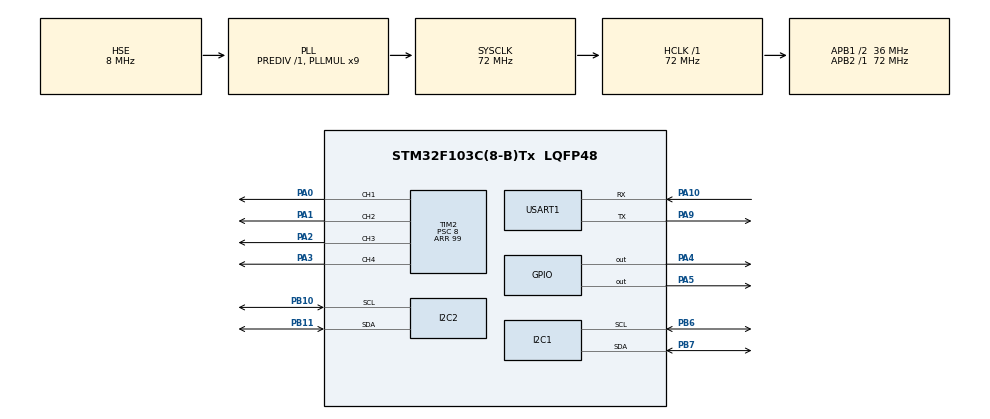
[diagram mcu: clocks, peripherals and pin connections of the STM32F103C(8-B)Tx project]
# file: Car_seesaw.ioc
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I2C2.I2C_Mode=I2C_Fast
Mcu.Family=STM32F1
Mcu.Name=STM32F103C(8-B)Tx
Mcu.Package=LQFP48
NVIC.PriorityGroup=NVIC_PRIORITYGROUP_4
NVIC.TIM1_UP_IRQn=true\:1\:0\:true\:false\:true\:true\:true
PA0-WKUP.Signal=S_TIM2_CH1_ETR
PA1.Signal=S_TIM2_CH2
PA10.Mode=Asynchronous
PA10.Signal=USART1_RX
PA13.Mode=Serial_Wire
PA13.Signal=SYS_JTMS-SWDIO
PA14.Mode=Serial_Wire
PA14.Signal=SYS_JTCK-SWCLK
PA2.Signal=S_TIM2_CH3
PA3.Signal=S_TIM2_CH4
PA4.GPIO_Speed=GPIO_SPEED_FREQ_HIGH
PA4.Signal=GPIO_Output
PA5.GPIO_Speed=GPIO_SPEED_FREQ_HIGH
PA5.Signal=GPIO_Output
PA9.Mode=Asynchronous
PA9.Signal=USART1_TX
PB10.Mode=I2C
PB10.Signal=I2C2_SCL
PB11.Mode=I2C
PB11.Signal=I2C2_SDA
PB6.Mode=I2C
PB6.Signal=I2C1_SCL
PB7.Mode=I2C
PB7.Signal=I2C1_SDA
PC14-OSC32_IN.Mode=LSE-External-Oscillator
PC14-OSC32_IN.Signal=RCC_OSC32_IN
PC15-OSC32_OUT.Mode=LSE-External-Oscillator
PC15-OSC32_OUT.Signal=RCC_OSC32_OUT
PD0-OSC_IN.Mode=HSE-External-Oscillator
PD0-OSC_IN.Signal=RCC_OSC_IN
PD1-OSC_OUT.Mode=HSE-External-Oscillator
PD1-OSC_OUT.Signal=RCC_OSC_OUT
ProjectManager.HeapSize=0x200
ProjectManager.StackSize=0x400
ProjectManager.TargetToolchain=MDK-ARM V5.27
RCC.AHBFreq_Value=72000000
RCC.APB1CLKDivider=RCC_HCLK_DIV2
RCC.APB1Freq_Value=36000000
RCC.APB1TimFreq_Value=72000000
RCC.APB2Freq_Value=72000000
RCC.APB2TimFreq_Value=72000000
RCC.HCLKFreq_Value=72000000
RCC.PLLMUL=RCC_PLL_MUL9
RCC.PLLSourceVirtual=RCC_PLLSOURCE_HSE
RCC.SYSCLKFreq_VALUE=72000000
RCC.SYSCLKSource=RCC_SYSCLKSOURCE_PLLCLK
RCC.USBFreq_Value=72000000
SH.S_TIM2_CH1_ETR.0=TIM2_CH1,PWM Generation1 CH1
SH.S_TIM2_CH2.0=TIM2_CH2,PWM Generation2 CH2
SH.S_TIM2_CH3.0=TIM2_CH3,PWM Generation3 CH3
SH.S_TIM2_CH4.0=TIM2_CH4,PWM Generation4 CH4
TIM1.Period=19999
TIM1.Prescaler=71
TIM2.Channel-PWM\ Generation1\ CH1=TIM_CHANNEL_1
TIM2.Channel-PWM\ Generation2\ CH2=TIM_CHANNEL_2
TIM2.Channel-PWM\ Generation3\ CH3=TIM_CHANNEL_3
TIM2.Channel-PWM\ Generation4\ CH4=TIM_CHANNEL_4
TIM2.Period=99
TIM2.Prescaler=8
USART1.VirtualMode=VM_ASYNC
VP_TIM1_VS_ClockSourceINT.Mode=Internal
board=custom

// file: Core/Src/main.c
/* USER CODE BEGIN Header */
/**
  ******************************************************************************
  * @file           : main.c
  * @brief          : Main program body
  ******************************************************************************
  * @attention
  *
  * <h2><center>&copy; Copyright (c) 2020 STMicroelectronics.
  * All rights reserved.</center></h2>
  *
  * This software component is licensed by ST under BSD 3-Clause license,
  * the "License"; You may not use this file except in compliance with the
  * License. You may obtain a copy of the License at:
  *                        opensource.org/licenses/BSD-3-Clause
  *
  ******************************************************************************
  */
/* USER CODE END Header */
#include "main.h"
#include "i2c.h"
#include "tim.h"
#include "usart.h"
#include "gpio.h"

/* USER CODE BEGIN Includes */
#include "gy-86.h"
#include "oled.h"
#include "motor.h"
#include "control.h"
/* USER CODE END Includes */

void SystemClock_Config(void);

int main(void)
{

  /* MCU Configuration--------------------------------------------------------*/

  /* Reset of all peripherals, Initializes the Flash interface and the Systick. */
  HAL_Init();

  /* Configure the system clock */
  SystemClock_Config();

  /* Initialize all configured peripherals */
  MX_GPIO_Init();
  MX_I2C1_Init();
  MX_I2C2_Init();
  MX_TIM2_Init();
  MX_USART1_UART_Init();
  MX_TIM1_Init();
  /* USER CODE BEGIN 2 */
	OLED_Init();
	OLED_Clear();
	OLED_ShowString(28,3,(uint8_t*)"Car_Seesaw",16);
	GY86_Init();
	Get_Init_Gravity();
	Motor_Init();
	OLED_Clear();

	HAL_TIM_Base_Start_IT(&htim1);
  /* USER CODE END 2 */

  /* Infinite loop */
  /* USER CODE BEGIN WHILE */
	//char buf[50];
  while (1)
  {
		//sprintf(buf,"Gyro_x= %+02.2f",Gyro_x/16.4f);
		OLED_ShowNum(48,2,Gx,4,16);
		//sprintf(buf,"CarAngle=%+02.2f",CarAngle);
		OLED_ShowNum(48,4,CarAngle,4,16);
    /* USER CODE END WHILE */

  }
}

void SystemClock_Config(void)
{
  RCC_OscInitTypeDef RCC_OscInitStruct = {0};
  RCC_ClkInitTypeDef RCC_ClkInitStruct = {0};

  /** Initializes the RCC Oscillators according to the specified parameters
  * in the RCC_OscInitTypeDef structure.
  */
  RCC_OscInitStruct.OscillatorType = RCC_OSCILLATORTYPE_HSE;
  RCC_OscInitStruct.HSEState = RCC_HSE_ON;
  RCC_OscInitStruct.HSEPredivValue = RCC_HSE_PREDIV_DIV1;
  RCC_OscInitStruct.HSIState = RCC_HSI_ON;
  RCC_OscInitStruct.PLL.PLLState = RCC_PLL_ON;
  RCC_OscInitStruct.PLL.PLLSource = RCC_PLLSOURCE_HSE;
  RCC_OscInitStruct.PLL.PLLMUL = RCC_PLL_MUL9;
  if (HAL_RCC_OscConfig(&RCC_OscInitStruct) != HAL_OK)
  {
    Error_Handler();
  }
  /** Initializes the CPU, AHB and APB buses clocks
  */
  RCC_ClkInitStruct.ClockType = RCC_CLOCKTYPE_HCLK|RCC_CLOCKTYPE_SYSCLK
                              |RCC_CLOCKTYPE_PCLK1|RCC_CLOCKTYPE_PCLK2;
  RCC_ClkInitStruct.SYSCLKSource = RCC_SYSCLKSOURCE_PLLCLK;
  RCC_ClkInitStruct.AHBCLKDivider = RCC_SYSCLK_DIV1;
  RCC_ClkInitStruct.APB1CLKDivider = RCC_HCLK_DIV2;
  RCC_ClkInitStruct.APB2CLKDivider = RCC_HCLK_DIV1;

  if (HAL_RCC_ClockConfig(&RCC_ClkInitStruct, FLASH_LATENCY_2) != HAL_OK)
  {
    Error_Handler();
  }
}

void Error_Handler(void)
{
}

/************************ (C) COPYRIGHT STMicroelectronics *****END OF FILE****/
